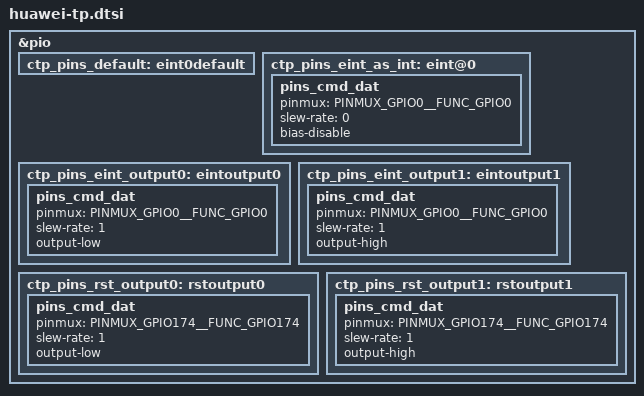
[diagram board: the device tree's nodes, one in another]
/* TOUCH start */
#include "../huawei_tpkit/bzd/huawei-tp.dtsi"
&pio {
	ctp_pins_default: eint0default {
	};
	ctp_pins_eint_as_int: eint@0 {
		pins_cmd_dat {
			pinmux = <PINMUX_GPIO0__FUNC_GPIO0>;
			slew-rate = <0>;
			bias-disable;
		};
	};
	ctp_pins_eint_output0: eintoutput0 {
		pins_cmd_dat {
			pinmux = <PINMUX_GPIO0__FUNC_GPIO0>;
			slew-rate = <1>;
			output-low;
		};
	};
	ctp_pins_eint_output1: eintoutput1 {
		pins_cmd_dat {
			pinmux = <PINMUX_GPIO0__FUNC_GPIO0>;
			slew-rate = <1>;
			output-high;
		};
	};
	ctp_pins_rst_output0: rstoutput0 {
		pins_cmd_dat {
			pinmux = <PINMUX_GPIO174__FUNC_GPIO174>;
			slew-rate = <1>;
			output-low;
		};
	};
	ctp_pins_rst_output1: rstoutput1 {
		pins_cmd_dat {
			pinmux = <PINMUX_GPIO174__FUNC_GPIO174>;
			slew-rate = <1>;
			output-high;
		};
	};
};
/* TOUCH end */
